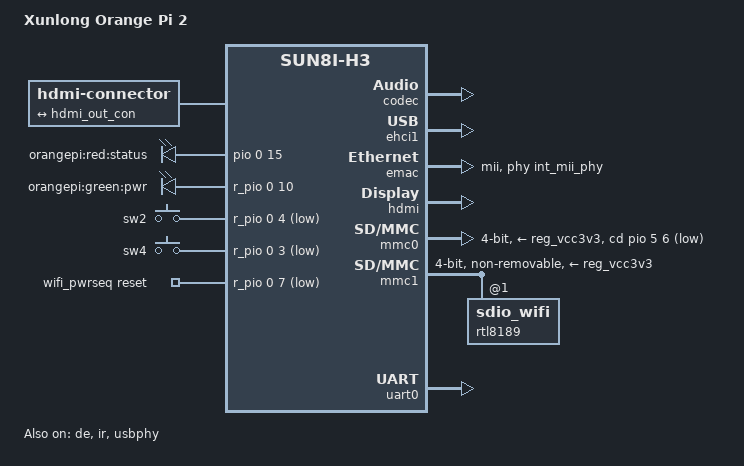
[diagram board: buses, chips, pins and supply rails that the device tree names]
/dts-v1/;
#include "sun8i-h3.dtsi"
#include "sunxi-common-regulators.dtsi"
#include <dt-bindings/gpio/gpio.h>
#include <dt-bindings/input/input.h>
/ {
	model = "Xunlong Orange Pi 2";
	compatible = "xunlong,orangepi-2", "allwinner,sun8i-h3";
	aliases {
		serial0 = &uart0;
		ethernet0 = &emac;
		ethernet1 = &rtl8189;
	};
	chosen {
		stdout-path = "serial0:115200n8";
	};
	connector {
		compatible = "hdmi-connector";
		type = "a";
		port {
			hdmi_con_in: endpoint {
				remote-endpoint = <&hdmi_out_con>;
			};
		};
	};
	leds {
		compatible = "gpio-leds";
		status_led {
			label = "orangepi:red:status";
			gpios = <&pio 0 15 GPIO_ACTIVE_HIGH>;
		};
		pwr_led {
			label = "orangepi:green:pwr";
			gpios = <&r_pio 0 10 GPIO_ACTIVE_HIGH>;
			default-state = "on";
		};
	};
	gpio-keys {
		compatible = "gpio-keys";
		switch-2 {
			label = "sw2";
			linux,code = <BTN_1>;
			gpios = <&r_pio 0 4 GPIO_ACTIVE_LOW>;
		};
		switch-4 {
			label = "sw4";
			linux,code = <KEY_POWER>;
			gpios = <&r_pio 0 3 GPIO_ACTIVE_LOW>;
			wakeup-source;
		};
	};
	wifi_pwrseq: wifi_pwrseq {
		compatible = "mmc-pwrseq-simple";
		reset-gpios = <&r_pio 0 7 GPIO_ACTIVE_LOW>;  
	};
};
&codec {
	allwinner,pa-gpios = <&pio 0 16 GPIO_ACTIVE_HIGH>;  
	allwinner,audio-routing =
		"Speaker", "LINEOUT",
		"MIC1", "Mic",
		"Mic",  "MBIAS";
	status = "okay";
};
&de {
	status = "okay";
};
&ehci1 {
	status = "okay";
};
&emac {
	phy-handle = <&int_mii_phy>;
	phy-mode = "mii";
	allwinner,leds-active-low;
	status = "okay";
};
&hdmi {
	status = "okay";
};
&hdmi_out {
	hdmi_out_con: endpoint {
		remote-endpoint = <&hdmi_con_in>;
	};
};
&ir {
	pinctrl-names = "default";
	pinctrl-0 = <&r_ir_rx_pin>;
	status = "okay";
};
&mmc0 {
	vmmc-supply = <&reg_vcc3v3>;
	bus-width = <4>;
	cd-gpios = <&pio 5 6 GPIO_ACTIVE_LOW>;  
	status = "okay";
};
&mmc1 {
	vmmc-supply = <&reg_vcc3v3>;
	mmc-pwrseq = <&wifi_pwrseq>;
	bus-width = <4>;
	non-removable;
	status = "okay";
	rtl8189: sdio_wifi@1 {
		reg = <1>;
	};
};
&reg_usb1_vbus {
	gpio = <&pio 6 13 GPIO_ACTIVE_HIGH>;
	status = "okay";
};
&uart0 {
	pinctrl-names = "default";
	pinctrl-0 = <&uart0_pa_pins>;
	status = "okay";
};
&uart1 {
	pinctrl-names = "default";
	pinctrl-0 = <&uart1_pins>;
	status = "disabled";
};
&uart2 {
	pinctrl-names = "default";
	pinctrl-0 = <&uart2_pins>;
	status = "disabled";
};
&uart3 {
	pinctrl-names = "default";
	pinctrl-0 = <&uart3_pins>;
	status = "disabled";
};
&usbphy {
	usb1_vbus-supply = <&reg_usb1_vbus>;
	status = "okay";
};
